# STM32F100ZET6 register map
File version: 1.0
Registers are 32-bit, access not given, reset 0x0 unless marked. A register's access mark holds for its fields unless they carry their own. Offsets are from the block's base; [hi:lo] are bit positions; {n}, {i} and the like mark numbered series; 'fields as' and 'values as' point back to an identical list.

## EXTI
Base 0x40010400
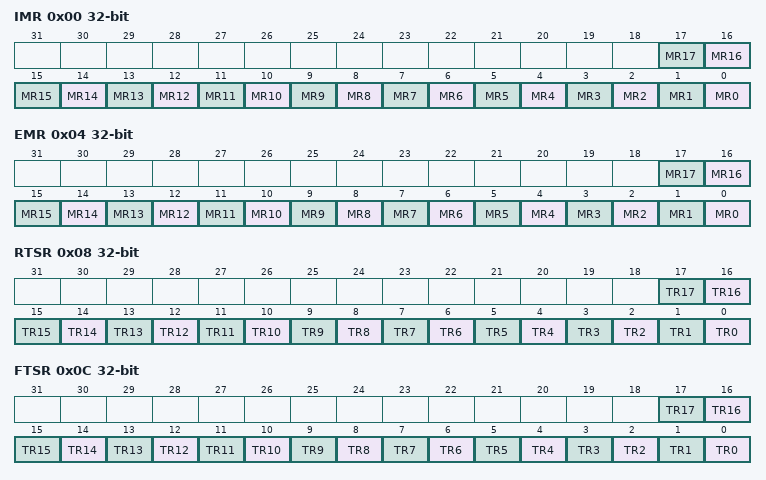
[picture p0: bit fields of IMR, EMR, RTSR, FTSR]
0x00 IMR
  [n] MR{n} (n=0..17)
0x04 EMR
  [n] MR{n} (n=0..17)
0x08 RTSR
  [n] TR{n} (n=0..17)
0x0C FTSR
  [n] TR{n} (n=0..17)
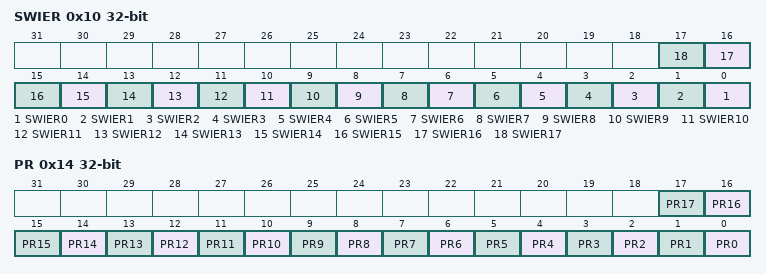
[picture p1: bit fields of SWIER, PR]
0x10 SWIER
  [n] SWIER{n} (n=0..17)
0x14 PR
  [n] PR{n} (n=0..17)

## GPIOA
Base 0x40010800
Same registers: GPIOB 0x40010C00, GPIOC 0x40011000, GPIOD 0x40011400, GPIOE 0x40011800, GPIOF 0x40011C00, GPIOG 0x40012000
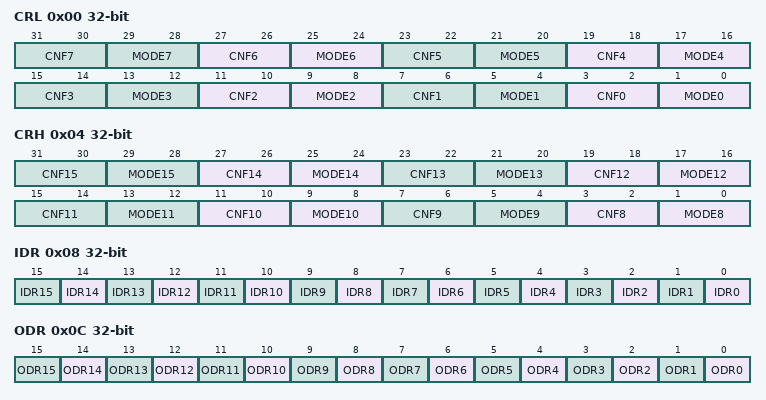
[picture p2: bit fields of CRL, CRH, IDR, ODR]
0x00 CRL
  [4n+3:4n+2] CNF{n} (n=0..7), [4n+1:4n] MODE{n} (n=0..7)
0x04 CRH
  [4n-29:4n-30] CNF{n} (n=8..15), [4n-31:4n-32] MODE{n} (n=8..15)
0x08 IDR
  [n] IDR{n} (n=0..15)
0x0C ODR
  [n] ODR{n} (n=0..15)
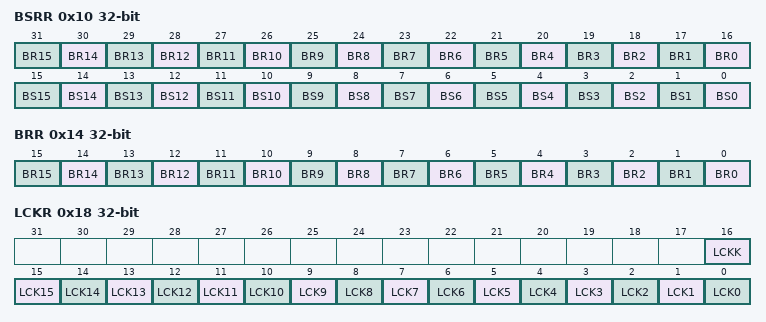
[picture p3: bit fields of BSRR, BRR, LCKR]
0x10 BSRR
  [n+16] BR{n} (n=0..15), [n] BS{n} (n=0..15)
0x14 BRR
  [n] BR{n} (n=0..15)
0x18 LCKR
  [16] LCKK, [n] LCK{n} (n=0..15)

## ADC1
Base 0x40012400
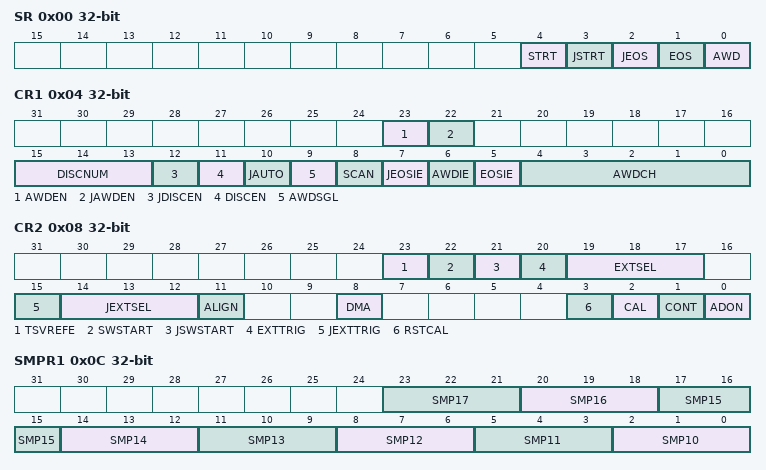
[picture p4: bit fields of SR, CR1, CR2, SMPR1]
0x00 SR
  [4] STRT, [3] JSTRT, [2] JEOS, [1] EOS, [0] AWD
0x04 CR1
  [23] AWDEN, [22] JAWDEN, [15:13] DISCNUM, [12] JDISCEN, [11] DISCEN, [10] JAUTO, [9] AWDSGL, [8] SCAN, [7] JEOSIE, [6] AWDIE, [5] EOSIE, [4:0] AWDCH
0x08 CR2
  [23] TSVREFE, [22] SWSTART, [21] JSWSTART, [20] EXTTRIG, [19:17] EXTSEL, [15] JEXTTRIG, [14:12] JEXTSEL, [11] ALIGN, [8] DMA, [3] RSTCAL, [2] CAL, [1] CONT, [0] ADON
0x0C SMPR1
  [3n-28:3n-30] SMP{n} (n=10..17)
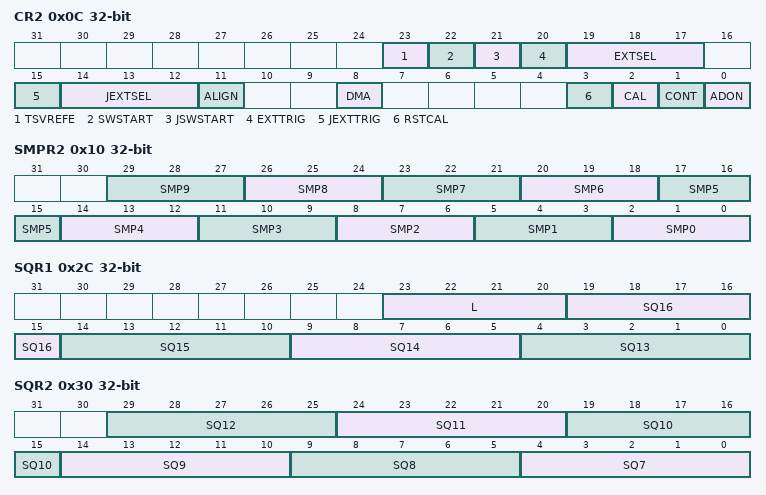
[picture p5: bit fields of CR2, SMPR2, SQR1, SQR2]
0x0C CR2
  fields as CR2
0x10 SMPR2
  [3n+2:3n] SMP{n} (n=0..9)
{0x10+4i} JOFR{i} (i=1..4)
  [11:0] JOFFSET{i}
0x24 HTR
  [11:0] HT
0x28 LTR
  [11:0] LT
0x2C SQR1
  [23:20] L, [5n-61:5n-65] SQ{n} (n=13..16)
0x30 SQR2
  [5n-31:5n-35] SQ{n} (n=7..12)
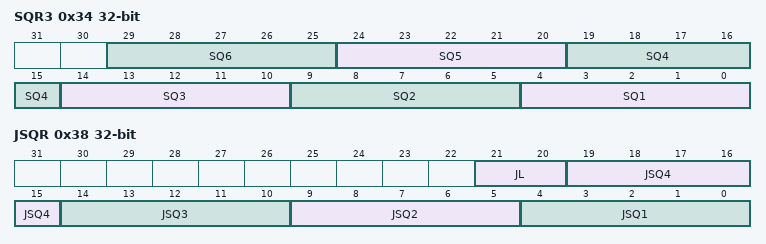
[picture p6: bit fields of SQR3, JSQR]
0x34 SQR3
  [5n-1:5n-5] SQ{n} (n=1..6)
0x38 JSQR
  [21:20] JL, [5n-1:5n-5] JSQ{n} (n=1..4)
{0x38+4i} JDR{i} (i=1..4)
  [15:0] JDATA
0x4C DR
  [15:0] DATA
0x58 DR
  [15:0] DATA

## DMA1
Base 0x40020000
Same registers: DMA2 0x40020400
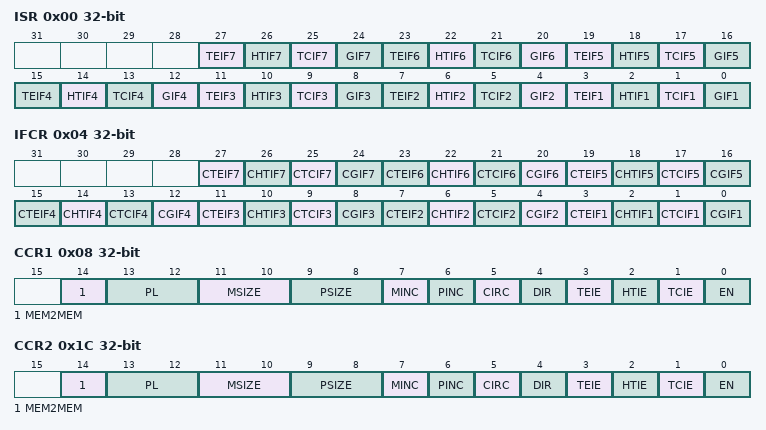
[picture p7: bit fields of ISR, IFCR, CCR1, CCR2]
0x00 ISR
  [4n-1] TEIF{n} (n=1..7), [4n-2] HTIF{n} (n=1..7), [4n-3] TCIF{n} (n=1..7), [4n-4] GIF{n} (n=1..7)
0x04 IFCR
  [4n-1] CTEIF{n} (n=1..7), [4n-2] CHTIF{n} (n=1..7), [4n-3] CTCIF{n} (n=1..7), [4n-4] CGIF{n} (n=1..7)
0x08 CCR1
  [14] MEM2MEM, [13:12] PL, [11:10] MSIZE, [9:8] PSIZE, [7] MINC, [6] PINC, [5] CIRC, [4] DIR, [3] TEIE, [2] HTIE, [1] TCIE, [0] EN
0x0C CNDTR1
  [15:0] NDT
0x10 CPAR1
  [31:0] PA
{0x0+0x14*i} CMAR{i} (i=1..7)
  [31:0] MA
0x1C CCR2
  fields as CCR1
0x20 CNDTR2
  [15:0] NDT
0x24 CPAR2
  [31:0] PA
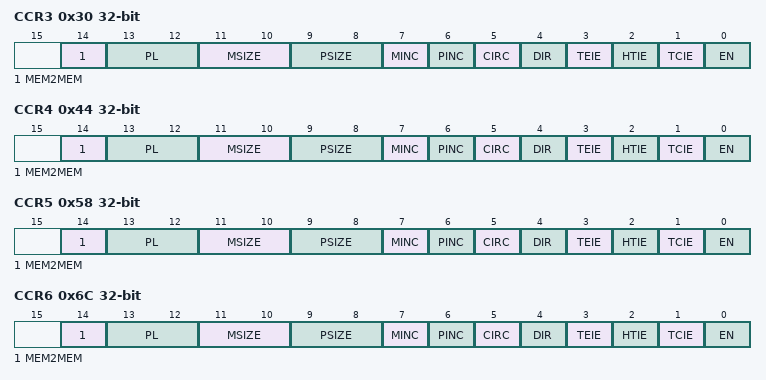
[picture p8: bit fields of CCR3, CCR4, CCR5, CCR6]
0x30 CCR3
  fields as CCR1
0x34 CNDTR3
  [15:0] NDT
0x38 CPAR3
  [31:0] PA
0x44 CCR4
  fields as CCR1
0x48 CNDTR4
  [15:0] NDT
0x4C CPAR4
  [31:0] PA
0x58 CCR5
  fields as CCR1
0x5C CNDTR5
  [15:0] NDT
0x60 CPAR5
  [31:0] PA
0x6C CCR6
  fields as CCR1
0x70 CNDTR6
  [15:0] NDT
0x74 CPAR6
  [31:0] PA
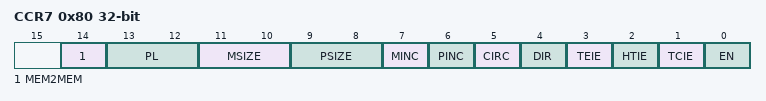
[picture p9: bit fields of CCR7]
0x80 CCR7
  fields as CCR1
0x84 CNDTR7
  [15:0] NDT
0x88 CPAR7
  [31:0] PA

## RCC
Base 0x40021000
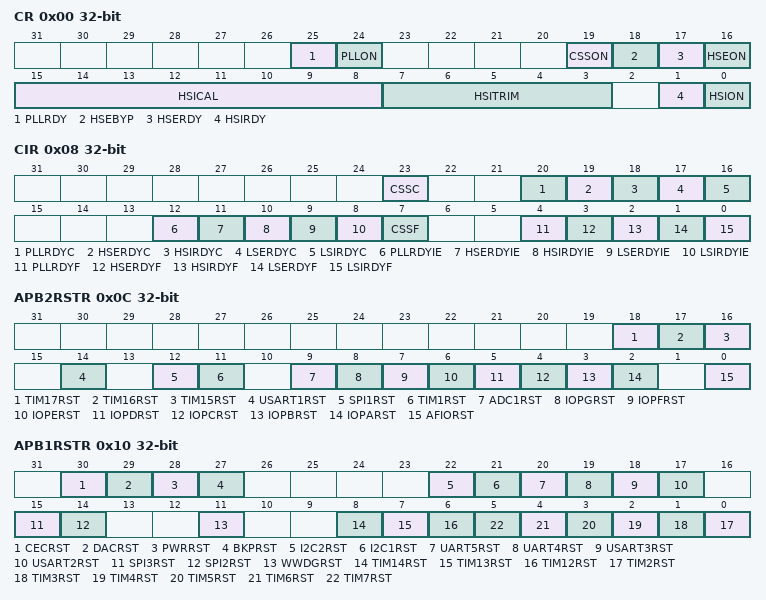
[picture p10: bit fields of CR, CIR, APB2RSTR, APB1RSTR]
0x00 CR
  [25] PLLRDY, [24] PLLON, [19] CSSON, [18] HSEBYP, [17] HSERDY, [16] HSEON, [15:8] HSICAL, [7:3] HSITRIM, [1] HSIRDY, [0] HSION
0x04 CFGR
  [26:24] MCO, [21] PLLMULL10, [20] PLLMULL6, [20:19] PLLMULL8, [20:18] PLLMULL9, [17] PLLXTPRE, [16] PLLSRC, [15:14] ADCPRE, [13:11] PPRE2, [10:8] PPRE1, [7:4] HPRE, [3:2] SWS, [1:0] SW
0x08 CIR
  [23] CSSC, [20] PLLRDYC, [19] HSERDYC, [18] HSIRDYC, [17] LSERDYC, [16] LSIRDYC, [12] PLLRDYIE, [11] HSERDYIE, [10] HSIRDYIE, [9] LSERDYIE, [8] LSIRDYIE, [7] CSSF, [4] PLLRDYF, [3] HSERDYF, [2] HSIRDYF, [1] LSERDYF, [0] LSIRDYF
0x0C APB2RSTR
  [18] TIM17RST, [17] TIM16RST, [16] TIM15RST, [14] USART1RST, [12] SPI1RST, [11] TIM1RST, [9] ADC1RST, [8] IOPGRST, [7] IOPFRST, [6] IOPERST, [5] IOPDRST, [4] IOPCRST, [3] IOPBRST, [2] IOPARST, [0] AFIORST
0x10 APB1RSTR
  [30] CECRST, [29] DACRST, [28] PWRRST, [27] BKPRST, [22] I2C2RST, [21] I2C1RST, [20] UART5RST, [19] UART4RST, [18] USART3RST, [17] USART2RST, [15] SPI3RST, [14] SPI2RST, [11] WWDGRST, [8] TIM14RST, [7] TIM13RST, [6] TIM12RST, [n-2] TIM{n}RST (n=2..7)
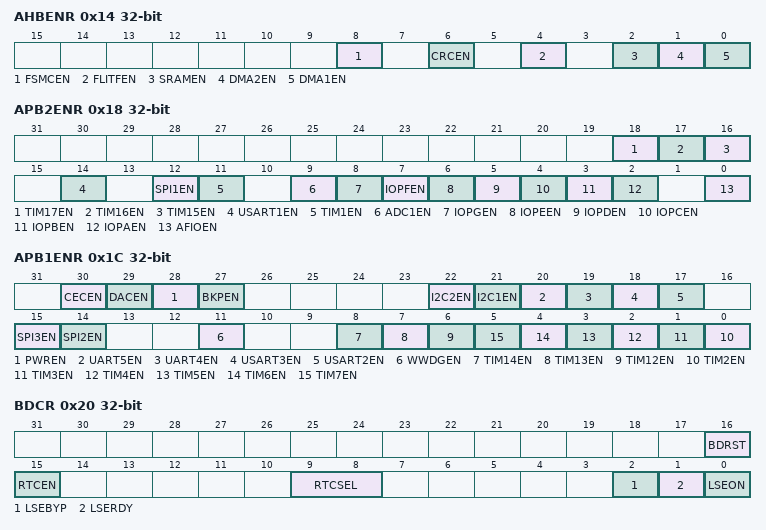
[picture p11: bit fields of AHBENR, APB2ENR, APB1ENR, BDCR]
0x14 AHBENR
  [8] FSMCEN, [6] CRCEN, [4] FLITFEN, [2] SRAMEN, [1] DMA2EN, [0] DMA1EN
0x18 APB2ENR
  [18] TIM17EN, [17] TIM16EN, [16] TIM15EN, [14] USART1EN, [12] SPI1EN, [11] TIM1EN, [9] ADC1EN, [8] IOPGEN, [7] IOPFEN, [6] IOPEEN, [5] IOPDEN, [4] IOPCEN, [3] IOPBEN, [2] IOPAEN, [0] AFIOEN
0x1C APB1ENR
  [30] CECEN, [29] DACEN, [28] PWREN, [27] BKPEN, [22] I2C2EN, [21] I2C1EN, [20] UART5EN, [19] UART4EN, [18] USART3EN, [17] USART2EN, [15] SPI3EN, [14] SPI2EN, [11] WWDGEN, [8] TIM14EN, [7] TIM13EN, [6] TIM12EN, [n-2] TIM{n}EN (n=2..7)
0x20 BDCR
  [16] BDRST, [15] RTCEN, [9:8] RTCSEL, [2] LSEBYP, [1] LSERDY, [0] LSEON
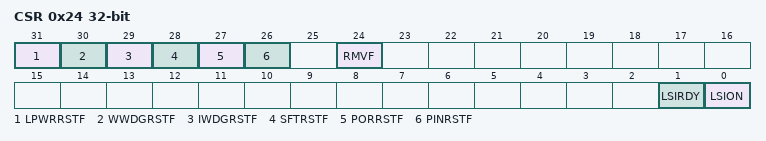
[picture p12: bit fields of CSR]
0x24 CSR
  [31] LPWRRSTF, [30] WWDGRSTF, [29] IWDGRSTF, [28] SFTRSTF, [27] PORRSTF, [26] PINRSTF, [24] RMVF, [1] LSIRDY, [0] LSION
0x2C CFGR2
  [3] PREDIV1_DIV9, [2] PREDIV1_DIV5, [2:1] PREDIV1_DIV7, [2:0] PREDIV1_DIV8

## FLASH
Base 0x40022000
0x00 ACR
  [3] HLFCYA
0x04 KEYR
  [31:0] FKEYR
0x08 OPTKEYR
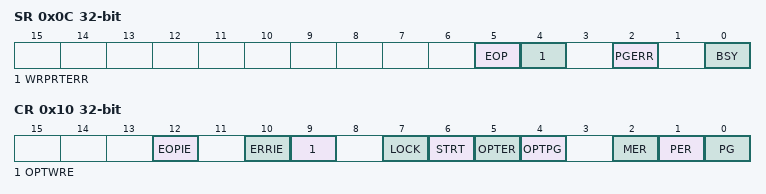
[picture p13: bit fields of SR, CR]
0x0C SR
  [5] EOP, [4] WRPRTERR, [2] PGERR, [0] BSY
0x10 CR
  [12] EOPIE, [10] ERRIE, [9] OPTWRE, [7] LOCK, [6] STRT, [5] OPTER, [4] OPTPG, [2] MER, [1] PER, [0] PG
0x14 AR
  [31:0] FAR
0x1C OBR
  [25:18] DATA1, [17:10] DATA0, [4] nRST_STDBY, [3] nRST_STOP, [4:2] USER, [1] RDPRT, [0] OPTERR
0x20 WRPR
  [31:0] WRP

## CRC
Base 0x40023000
0x00 DR
0x04 IDR 8-bit
0x08 CR
  [0] RESET

## FSMC_Bank1
Base 0xA0000000
0x00 BTCR.0
  [29:28] ACCMOD, [27:24] DATLAT, [23:20] CLKDIV, [19] CBURSTRW, [19:16] BUSTURN, [15] ASYNCWAIT, [14] EXTMOD, [13] WAITEN, [12] WREN, [11] WAITCFG, [10] WRAPMOD, [9] WAITPOL, [15:8] DATAST, [6] FACCEN, [5:4] MWID, [3:2] MTYP, [1] MUXEN, [0] MBKEN
0x04 BTCR.1
  fields as BTCR.0
0x08 BTCR.2
  fields as BTCR.0
0x0C BTCR.3
  fields as BTCR.0
0x10 BTCR.4
  fields as BTCR.0
0x14 BTCR.5
  fields as BTCR.0
0x18 BTCR.6
  fields as BTCR.0
0x1C BTCR.7
  fields as BTCR.0

## FSMC_Bank1E
Base 0xA0000104
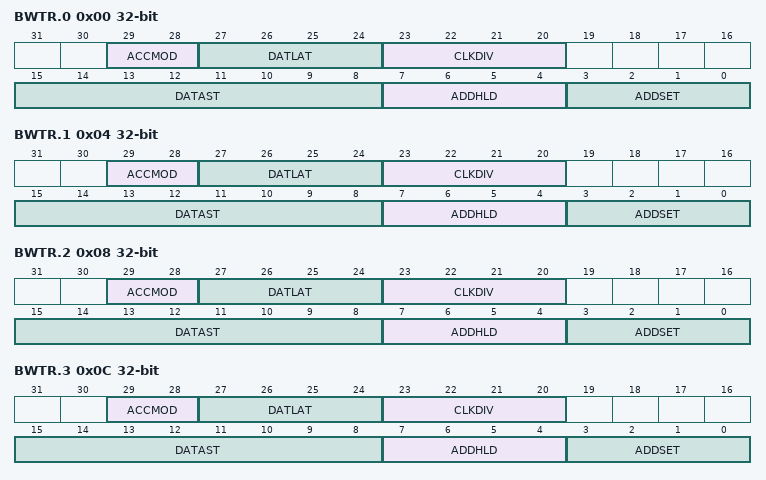
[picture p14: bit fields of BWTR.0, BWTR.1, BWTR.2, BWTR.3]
0x00 BWTR.0
  [29:28] ACCMOD, [27:24] DATLAT, [23:20] CLKDIV, [15:8] DATAST, [7:4] ADDHLD, [3:0] ADDSET
0x04 BWTR.1
  fields as BWTR.0
0x08 BWTR.2
  fields as BWTR.0
0x0C BWTR.3
  fields as BWTR.0
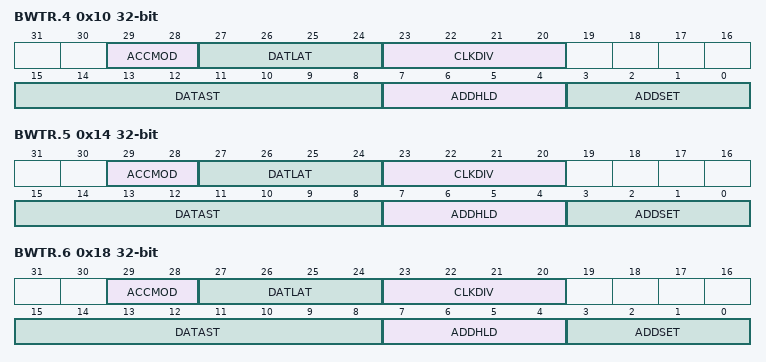
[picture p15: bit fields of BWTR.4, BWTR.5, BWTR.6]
0x10 BWTR.4
  fields as BWTR.0
0x14 BWTR.5
  fields as BWTR.0
0x18 BWTR.6
  fields as BWTR.0

## DBGMCU
Base 0xE0042000
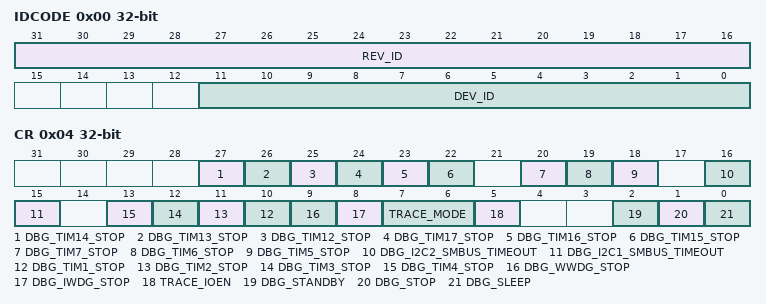
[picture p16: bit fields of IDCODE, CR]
0x00 IDCODE
  [31:16] REV_ID, [11:0] DEV_ID
0x04 CR
  [27] DBG_TIM14_STOP, [26] DBG_TIM13_STOP, [25] DBG_TIM12_STOP, [24] DBG_TIM17_STOP, [23] DBG_TIM16_STOP, [22] DBG_TIM15_STOP, [20] DBG_TIM7_STOP, [19] DBG_TIM6_STOP, [18] DBG_TIM5_STOP, [16] DBG_I2C2_SMBUS_TIMEOUT, [15] DBG_I2C1_SMBUS_TIMEOUT, [n+9] DBG_TIM{n}_STOP (n=1..4), [9] DBG_WWDG_STOP, [8] DBG_IWDG_STOP, [7:6] TRACE_MODE, [5] TRACE_IOEN, [2] DBG_STANDBY, [1] DBG_STOP, [0] DBG_SLEEP
